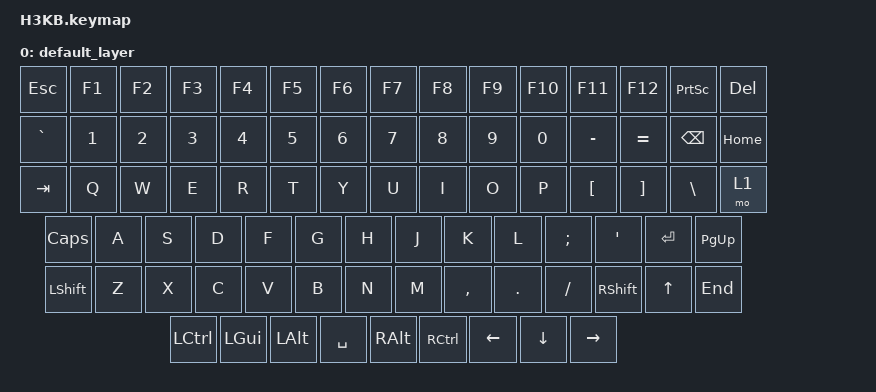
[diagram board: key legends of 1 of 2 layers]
/*
 * Copyright (c) 2024
 *
 * SPDX-License-Identifier: MIT
 */

#include <behaviors.dtsi>
#include <dt-bindings/zmk/keys.h>
#include <dt-bindings/zmk/bt.h>

/ {
    keymap0: keymap {
        compatible = "zmk,keymap";

        default_layer {
// -----------------------------------------------------------------------------------------------
// |  ESC  | F1 | F2 | F3 | F4 | F5 | F6 | F7 | F8 | F9 | F10 | F11 | F12 | PRTSC |   DEL       |
// | ` |  1  |  2  |  3  |  4  |  5  |  6  |  7  |  8  |  9  |  0  |  -  |  =  |   BKSP  | HOME |
// | TAB  |  Q  |  W  |  E  |  R  |  T  |  Y  |  U  |  I  |  O  |  P  |  [  |  ]  |  "|" | MO1 |
// | CAPS  |  A  |  S  |  D  |  F  |  G  |  H  |  J  |  K  |  L  |  ;  |  '  |   ENTER   | PG UP |
// |  SHIFT  |  Z  |  X  |  C  |  V  |  B  |  N  |  M  |  ,  |  .  |  /  |    SHIFT  | UP | END |
// |  CTL  |  WIN  |  ALT  |               SPACE                |  ALT  |   CTL  | LT | DN | RT |
// -----------------------------------------------------------------------------------------------
bindings = <
&kp ESC  &kp F1 &kp F2 &kp F3 &kp F4 &kp F5 &kp F6 &kp F7 &kp F8 &kp F9 &kp F10 &kp F11 &kp F12 &kp PSCRN     &kp DEL
&kp GRAVE &kp N1 &kp N2 &kp N3 &kp N4 &kp N5 &kp N6 &kp N7 &kp N8 &kp N9 &kp N0 &kp MINUS &kp EQUAL  &kp BSPC &kp HOME
&kp TAB  &kp Q  &kp W  &kp E  &kp R  &kp T  &kp Y  &kp U  &kp I  &kp O  &kp P  &kp LBKT  &kp RBKT  &kp BSLH   &mo 1
&kp CLCK  &kp A  &kp S  &kp D  &kp F  &kp G  &kp H  &kp J  &kp K  &kp L  &kp SEMI &kp SQT           &kp RET   &kp PG_UP
&kp LSHFT   &kp Z  &kp X  &kp C  &kp V  &kp B  &kp N  &kp M  &kp COMMA &kp DOT &kp FSLH      &kp RSHFT &kp UP &kp END
&kp LCTRL &kp LGUI &kp LALT               &kp SPACE                   &kp RALT  &kp RCTRL  &kp LEFT  &kp DOWN &kp RIGHT
        >;
    };

    rgb_layer {
// -------------------------------------------------------------------------------------------------
// |  ESC  | F1 | F2 | F3 | F4 | F5 | F6 | F7 | F8 | F9 | F10 | F11 | F12 | PRTSC |   BT_CLR      |
// | ` |  1  |  2  |  3  |  4  |  5  |  6  |  7  |  8  |  9  |  0  |  -  |  =  |   BT 1  | HOME |
// | TAB  |  Q  |  W  |  E  |  R  |  T  |  Y  |  U  |  I  |  O  |  P  |  [  |  ]  |  BT 2 | M01 |
// | CAPS  |  A  |  S  |  D  |  F  |  G  |  H  |  J  |  K  |  L  |  ;  |  '  |   BT 3   | PG UP |
// |  SHIFT  |  Z  |  X  |  C  |  V  |  B  |  N  |  M  |  ,  |  .  |  /  |    BT 4  | UP | END |
// |  CTL  |  WIN  |  ALT  |               SPACE                |  ALT  |   CTL  | T | DN | LT |
// --------------------------------------------------------------------------------------------------
        bindings = <
&trans  &trans  &trans  &trans  &trans  &trans  &trans  &trans  &trans  &trans  &trans  &trans &trans   &bt BT_CLR
&trans &trans  &trans  &trans  &trans  &trans  &trans  &trans  &trans  &trans  &trans  &trans &trans  &bt BT_SEL 0 &trans
&trans  &trans  &trans  &trans  &trans  &trans  &trans  &trans  &trans  &trans  &trans  &trans  &trans   &bt BT_SEL 1   &mo1
&trans  &trans  &trans  &trans  &trans  &trans  &trans  &trans  &trans  &trans  &trans  &trans &bt BT_SEL 2   &trans
&trans   &trans  &trans  &trans  &trans  &trans  &trans  &trans  &trans  &trans  &trans     &bt BT_SEL 3 &trans &trans
&trans &trans &trans                    &trans                      &trans   &trans   &trans  &trans &trans
        >;
    };
};
};

